AUTOSAR XML (schema 4-2-2)
package /Components
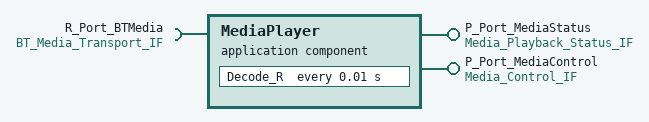
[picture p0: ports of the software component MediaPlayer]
  application sw component type MediaPlayer
    provide port P_Port_MediaStatus: provided-interface=Media_Playback_Status_IF
    provide port P_Port_MediaControl: provided-interface=Media_Control_IF
    require port R_Port_BTMedia: required-interface=BT_Media_Transport_IF
    behavior MediaPlayer_Internal
      data received event AudioFrame_Received: start-on-event=Audio_Receive_R
      init event MediaPlayer_Init: start-on-event=Init_R
      operation invoked event MediaControl_Called: start-on-event=Handle_Control_R
      timing event MediaPlayer_Periodic: start-on-event=Decode_R, period=0.01
      4 x runnable:
        Init_R: symbol=MediaPlayer_Init_R
          data-receive-point-by-arguments:
            access Read_Init_SampleRate: accessed-variable=R_Port_BTMedia.sample_rate_hz
          data-send-points:
            access Send_Init_PlayState: accessed-variable=P_Port_MediaStatus.play_state
            access Send_Init_TrackTitle: accessed-variable=P_Port_MediaStatus.track_title
            access Send_Init_ElapsedMs: accessed-variable=P_Port_MediaStatus.elapsed_ms
          data-write-access:
            access Write_Init_PlayState: accessed-variable=P_Port_MediaStatus.play_state
            access Write_Init_TrackTitle: accessed-variable=P_Port_MediaStatus.track_title
            access Write_Init_ElapsedMs: accessed-variable=P_Port_MediaStatus.elapsed_ms
          parameter access ParamInit_SampleRate: accessed-parameter=R_Port_BTMedia.sample_rate_hz
          parameter access ParamInit_Channels: accessed-parameter=R_Port_BTMedia.channels
        Decode_R: minimum-start-interval=0.01, symbol=MediaPlayer_Decode_R
          data-receive-point-by-arguments:
            access Read_AudioFrame: accessed-variable=R_Port_BTMedia.audio_pcm_frame
            access Read_SampleRate: accessed-variable=R_Port_BTMedia.sample_rate_hz
            access Read_Channels: accessed-variable=R_Port_BTMedia.channels
          data-send-points:
            access Send_PlayState: accessed-variable=P_Port_MediaStatus.play_state
            access Send_ElapsedMs: accessed-variable=P_Port_MediaStatus.elapsed_ms
            access Send_TrackTitle: accessed-variable=P_Port_MediaStatus.track_title
          data-write-access:
            access Write_PlayState: accessed-variable=P_Port_MediaStatus.play_state
            access Write_ElapsedMs: accessed-variable=P_Port_MediaStatus.elapsed_ms
            access Write_TrackTitle: accessed-variable=P_Port_MediaStatus.track_title
          parameter access Param_Decode_SampleRate: accessed-parameter=R_Port_BTMedia.sample_rate_hz
        Handle_Control_R: symbol=MediaPlayer_Handle_Control_R
          data-receive-point-by-arguments:
            access Read_Control_SampleRate: accessed-variable=R_Port_BTMedia.sample_rate_hz
          data-send-points:
            access Send_Control_PlayState: accessed-variable=P_Port_MediaStatus.play_state
            access Send_Control_ElapsedMs: accessed-variable=P_Port_MediaStatus.elapsed_ms
            access Send_Control_TrackTitle: accessed-variable=P_Port_MediaStatus.track_title
          data-write-access:
            access Write_Control_PlayState: accessed-variable=P_Port_MediaStatus.play_state
            access Write_Control_ElapsedMs: accessed-variable=P_Port_MediaStatus.elapsed_ms
            access Write_Control_TrackTitle: accessed-variable=P_Port_MediaStatus.track_title
          parameter access Param_Control_CurrentState: accessed-parameter=P_Port_MediaStatus.play_state
        Audio_Receive_R: symbol=MediaPlayer_Audio_Receive_R
          data-receive-point-by-arguments:
            access Read_Received_AudioFrame: accessed-variable=R_Port_BTMedia.audio_pcm_frame
          data-send-points:
            access Send_Received_PlayState: accessed-variable=P_Port_MediaStatus.play_state
          data-write-access:
            access Write_Received_PlayState: accessed-variable=P_Port_MediaStatus.play_state
          parameter access Param_AudioReceive_Channels: accessed-parameter=R_Port_BTMedia.channels
